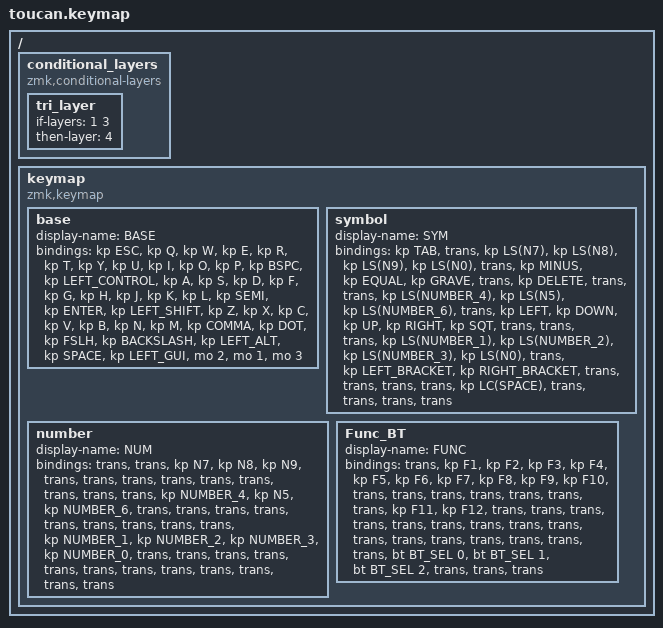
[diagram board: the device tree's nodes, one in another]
#include <behaviors.dtsi>
#include <dt-bindings/zmk/bt.h>
#include <dt-bindings/zmk/keys.h>

#define BASE 0
#define NAV  1
#define SYM  2
#define ADJ  3

/ {
    conditional_layers {
        compatible = "zmk,conditional-layers";

        tri_layer {
            if-layers = <1 3>;
            then-layer = <4>;
        };
    };

    keymap {
        compatible = "zmk,keymap";

        base {
            display-name = "BASE";
            bindings = <
&kp ESC  &kp Q  &kp W  &kp E  &kp R  &kp T  &kp Y  &kp U  &kp I  &kp O  &kp P  &kp BSPC  &kp LEFT_CONTROL  &kp A  &kp S  &kp D  &kp F  &kp G  &kp H  &kp J  &kp K  &kp L  &kp SEMI  &kp ENTER  &kp LEFT_SHIFT  &kp Z  &kp X  &kp C  &kp V  &kp B  &kp N  &kp M  &kp COMMA  &kp DOT  &kp FSLH  &kp BACKSLASH  &kp LEFT_ALT  &kp SPACE  &kp LEFT_GUI  &mo 2  &mo 1  &mo 3
            >;
        };

        symbol {
            display-name = "SYM";
            bindings = <
&kp TAB  &trans  &kp LS(N7)  &kp LS(N8)  &kp LS(N9)  &kp LS(N0)  &trans  &kp MINUS  &kp EQUAL  &kp GRAVE  &trans  &kp DELETE  &trans  &trans  &kp LS(NUMBER_4)  &kp LS(N5)  &kp LS(NUMBER_6)  &trans  &kp LEFT  &kp DOWN  &kp UP  &kp RIGHT  &kp SQT  &trans  &trans  &trans  &kp LS(NUMBER_1)  &kp LS(NUMBER_2)  &kp LS(NUMBER_3)  &kp LS(N0)  &trans  &kp LEFT_BRACKET  &kp RIGHT_BRACKET  &trans  &trans  &trans  &trans  &kp LC(SPACE)  &trans  &trans  &trans  &trans
            >;
        };

        number {
            display-name = "NUM";
            bindings = <
&trans  &trans  &kp N7  &kp N8  &kp N9  &trans  &trans  &trans  &trans  &trans  &trans  &trans  &trans  &trans  &kp NUMBER_4  &kp N5  &kp NUMBER_6  &trans  &trans  &trans  &trans  &trans  &trans  &trans  &trans  &trans  &kp NUMBER_1  &kp NUMBER_2  &kp NUMBER_3  &kp NUMBER_0  &trans  &trans  &trans  &trans  &trans  &trans  &trans  &trans  &trans  &trans  &trans  &trans
            >;
        };

        Func_BT {
            display-name = "FUNC";
            bindings = <
&trans  &kp F1  &kp F2  &kp F3  &kp F4  &kp F5  &kp F6  &kp F7  &kp F8  &kp F9  &kp F10  &trans  &trans  &trans  &trans  &trans  &trans  &trans  &kp F11  &kp F12  &trans  &trans  &trans  &trans  &trans  &trans  &trans  &trans  &trans  &trans  &trans  &trans  &trans  &trans  &trans  &trans  &bt BT_SEL 0  &bt BT_SEL 1  &bt BT_SEL 2  &trans  &trans  &trans
            >;
        };
    };
};
